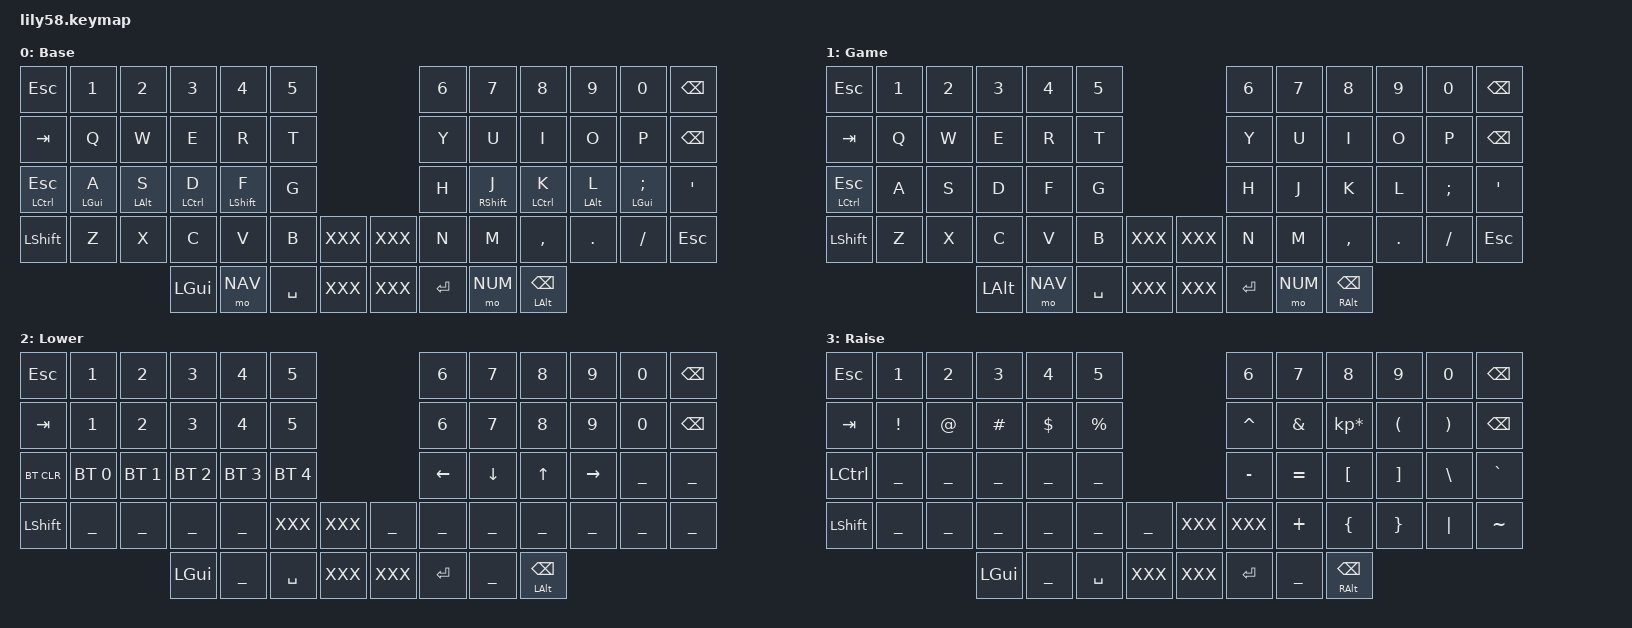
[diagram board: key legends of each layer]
#define CONFIG_WIRELESS
#define LILY58_STANDARD_LABELS
#include "zmk-helpers/key-labels/lily58.h"
#include "base.keymap"



/* Keymap */
/*                                      58 KEY MATRIX / LAYOUT MAPPING

  ╭────────────────────────────┬────────────────────────────╮ ╭─────────────────────────────┬─────────────────────────────╮
  │  0   1   2   3   4   5     │      6   7   8   9  10  11 │ │ LN5 LN4 LN3 LN2 LN1 LN0     │     RN0 RN1 RN2 RN3 RN4 RN5 │
  │ 12  13  14  15  16  17     │     18  19  20  21  22  23 │ │ LT5 LT4 LT3 LT2 LT1 LT0     │     RT0 RT1 RT2 RT3 RT4 RT5 │
  │ 24  25  26  27  28  29     │     30  31  32  33  34  35 │ │ LM5 LM4 LM3 LM2 LM1 LM0     │     RM0 RM1 RM2 RM3 RM4 RM5 │
  │ 36  37  38  39  40  41  42 │ 43  44  45  46  47  48  49 │ │ LB5 LB4 LB3 LB2 LB1 LB0 LEC │ REC RB0 RB1 RB2 RB3 RB4 RB5 │
  ╰───────────╮ 50  51  52  53 │ 54  55  56  57 ╭───────────╯ ╰───────────╮ LH3 LH2 LH1 LH0 │ RH0 RH1 RH2 RH3 ╭───────────╯
              ╰────────────────┴────────────────╯                         ╰─────────────────┴─────────────────╯             */

ZMK_LAYER(Base,
    &kp ESC       &kp N1       &kp N2       &kp N3          &kp N4       &kp N5                   &kp N6   &kp N7         &kp N8          &kp N9        &kp N0            &kp BSPC
    &kp TAB       &kp Q        &kp W        &kp E           &kp R        &kp T                    &kp Y    &kp U          &kp I           &kp O         &kp P             &kp BSPC
    &mt LCTRL ESC &hml LGUI A  &hml LALT S  &hml LCTRL D    &hml LSHFT F &kp G                    &kp H    &hmr RSHFT J   &hmr LCTRL K    &hmr LALT L   &hmr LGUI SEMI    &kp SQT
    &kp LSHFT     &kp Z        &kp X        &kp C           &kp V        &kp B      XXX XXX       &kp N    &kp M          &kp COMMA       &kp DOT       &kp FSLH          &kp ESC
                                            &kp LGUI        &mo NAV      &kp SPACE  XXX XXX       &kp RET  &mo NUM        &mt LALT BSPC     
)

ZMK_LAYER(Game,
     &kp ESC       &kp N1       &kp N2       &kp N3          &kp N4       &kp N5                   &kp N6   &kp N7         &kp N8          &kp N9        &kp N0            &kp BSPC
    &kp TAB        &kp Q  &kp W  &kp E     &kp R    &kp T        &kp Y    &kp U    &kp I          &kp O    &kp P     &kp BSPC
    &mt LCTRL ESC  &kp A  &kp S  &kp D     &kp F    &kp G        &kp H    &kp J    &kp K          &kp L    &kp SEMI  &kp SQT
    &kp LSHFT      &kp Z  &kp X  &kp C     &kp V    &kp B      XXX XXX          &kp N    &kp M    &kp COMMA      &kp DOT  &kp FSLH  &kp ESC
                                 &kp LALT &mo NAV   &kp SPACE  XXX XXX  &kp RET  &mo NUM  &mt RALT BSPC    
)
ZMK_LAYER(Lower,
     &kp ESC       &kp N1       &kp N2       &kp N3          &kp N4       &kp N5                   &kp N6   &kp N7         &kp N8          &kp N9        &kp N0            &kp BSPC
    &kp TAB     &kp N1        &kp N2        &kp N3        &kp N4        &kp N5          &kp N6    &kp N7    &kp N8         &kp N9     &kp N0  &kp BSPC
    &bt BT_CLR  &bt BT_SEL 0  &bt BT_SEL 1  &bt BT_SEL 2  &bt BT_SEL 3  &bt BT_SEL 4    &kp LEFT  &kp DOWN  &kp UP         &kp RIGHT  ___     ___
    &kp LSHFT   ___           ___           ___           ___           XXX XXX  ___             ___       ___       ___            ___        ___     ___
                              &kp LGUI      ___           &kp SPACE     XXX XXX &kp RET         ___       &mt LALT BSPC  
)

ZMK_LAYER(Raise,
    &kp ESC       &kp N1       &kp N2       &kp N3          &kp N4       &kp N5                   &kp N6   &kp N7         &kp N8          &kp N9        &kp N0            &kp BSPC
    &kp TAB    &kp EXCL  &kp AT  &kp HASH  &kp DLLR  &kp PRCNT           &kp CARET  &kp AMPS   &kp KP_MULTIPLY  &kp LPAR  &kp RPAR  &kp BSPC
    &kp LCTRL  ___    ___  ___    ___      ___       &kp MINUS           &kp EQUAL  &kp LBKT         &kp RBKT  &kp BSLH  &kp GRAVE
    &kp LSHFT  ___    ___  ___    ___      ___       &kp UNDER   XXX XXX &kp PLUS   &kp LBRC         &kp RBRC  &kp PIPE  &kp TILDE
                                 &kp LGUI  ___       &kp SPACE   XXX XXX &kp RET    ___     &mt RALT BSPC   
)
